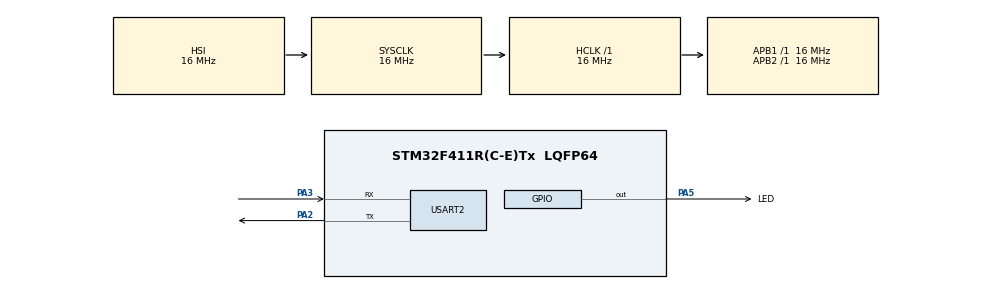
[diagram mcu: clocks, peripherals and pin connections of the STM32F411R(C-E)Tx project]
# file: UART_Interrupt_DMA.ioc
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Dma.Request0=USART2_TX
Dma.USART2_TX.0.Direction=DMA_MEMORY_TO_PERIPH
Dma.USART2_TX.0.FIFOMode=DMA_FIFOMODE_DISABLE
Dma.USART2_TX.0.Instance=DMA1_Stream6
Dma.USART2_TX.0.MemDataAlignment=DMA_MDATAALIGN_BYTE
Dma.USART2_TX.0.MemInc=DMA_MINC_ENABLE
Dma.USART2_TX.0.Mode=DMA_NORMAL
Dma.USART2_TX.0.PeriphDataAlignment=DMA_PDATAALIGN_BYTE
Dma.USART2_TX.0.PeriphInc=DMA_PINC_DISABLE
Dma.USART2_TX.0.Priority=DMA_PRIORITY_LOW
Mcu.Family=STM32F4
Mcu.Name=STM32F411R(C-E)Tx
Mcu.Package=LQFP64
NVIC.DMA1_Stream6_IRQn=true\:0\:0\:false\:false\:true\:false\:true\:true
NVIC.PriorityGroup=NVIC_PRIORITYGROUP_4
NVIC.USART2_IRQn=true\:0\:0\:false\:false\:true\:true\:true\:true
PA2.Mode=Asynchronous
PA2.Signal=USART2_TX
PA3.Mode=Asynchronous
PA3.Signal=USART2_RX
PA5.GPIO_Label=LED
PA5.Signal=GPIO_Output
ProjectManager.HeapSize=0x200
ProjectManager.StackSize=0x400
ProjectManager.TargetToolchain=STM32CubeIDE
RCC.AHBFreq_Value=16000000
RCC.APB1Freq_Value=16000000
RCC.APB2Freq_Value=16000000
RCC.CortexFreq_Value=16000000
RCC.HSE_VALUE=25000000
RCC.HSI_VALUE=16000000
RCC.LSE_VALUE=32768
RCC.SYSCLKFreq_VALUE=16000000
RCC.VCOOutputFreq_Value=192000000
USART2.VirtualMode=VM_ASYNC
board=custom

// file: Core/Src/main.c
/* USER CODE BEGIN Header */
/**
  ******************************************************************************
  * @file           : main.c
  * @brief          : Main program body
  ******************************************************************************
  * @attention
  *
  * Copyright (c) 2025 STMicroelectronics.
  * All rights reserved.
  *
  * This software is licensed under terms that can be found in the LICENSE file
  * in the root directory of this software component.
  * If no LICENSE file comes with this software, it is provided AS-IS.
  *
  ******************************************************************************
  */
/* USER CODE END Header */
#include "main.h"

/* USER CODE BEGIN Includes */
#include <stdbool.h>

/* USER CODE END Includes */

UART_HandleTypeDef huart2;
DMA_HandleTypeDef hdma_usart2_tx;

void SystemClock_Config(void);
static void MX_GPIO_Init(void);
static void MX_DMA_Init(void);
static void MX_USART2_UART_Init(void);

/* USER CODE BEGIN 0 */

uint8_t TxData[10240];
bool isSet = true; //The data is transmitted only when this flag is set

uint32_t CountInterrupts = 0;
uint32_t CountLoops = 0;

uint8_t value = 1; //Value to stuff in the array of data

//This function will be called when the the 1st half of data has been transfered.
//The 2nd half will be transfered by DMA
void HAL_UART_TxHalfCpltCallback(UART_HandleTypeDef *huart)
{
	for (uint32_t i = 0; i < 5120; ++i)
	{
		TxData[i] = value;
	}
}
//-----------------------------------------------------------
void HAL_UART_TxCpltCallback(UART_HandleTypeDef *huart)
{
	isSet = true;
	++CountInterrupts;
}
/* USER CODE END 0 */

int main(void)
{

  /* USER CODE BEGIN 1 */

	//Blocking mode (not shown) is used to send a little amount of data.
	//Interrupt mode is used to send big amount of data.
	//DMA mode is used to quick access to huge amount of data without affecting the CPU load.

  /* USER CODE END 1 */

  /* MCU Configuration--------------------------------------------------------*/

  /* Reset of all peripherals, Initializes the Flash interface and the Systick. */
  HAL_Init();

  /* Configure the system clock */
  SystemClock_Config();

  /* Initialize all configured peripherals */
  MX_GPIO_Init();
  MX_DMA_Init();
  MX_USART2_UART_Init();
  /* USER CODE BEGIN 2 */

  for (int i = 0; i < 10240; ++i)
  {
	  TxData[i] = i & (0xff);
  }

  //HAL_UART_Transmit_DMA(&huart2, TxData, 10240); //In the circular the data transfer will repeat faster than 1 s.
  //It does not affect the CPU load
  /* USER CODE END 2 */

  /* Infinite loop */
  /* USER CODE BEGIN WHILE */
  while (1)
  {
    //UART with Interrupts sends data using the CPU
	  if (isSet)
    {
    	HAL_UART_Transmit_IT(&huart2, TxData, 10240); //It tale approximately 1s to transmit the 10 Kb of data
    	isSet = false;
    }

	//UART with DMA transfers data without using the CPU and can work with huge amount of data
	if (isSet)
	{
		HAL_UART_Transmit_DMA(&huart2, TxData, 10240);
		isSet = 0;
	}
	//--------------------------------------------------------------------------------------------
    HAL_GPIO_TogglePin(GPIOA, GPIO_PIN_5);
    HAL_Delay(500);
    ++CountLoops;

    /* USER CODE END WHILE */

  }
}

void SystemClock_Config(void)
{
  RCC_OscInitTypeDef RCC_OscInitStruct = {0};
  RCC_ClkInitTypeDef RCC_ClkInitStruct = {0};

  /** Configure the main internal regulator output voltage
  */
  __HAL_RCC_PWR_CLK_ENABLE();
  __HAL_PWR_VOLTAGESCALING_CONFIG(PWR_REGULATOR_VOLTAGE_SCALE1);

  /** Initializes the RCC Oscillators according to the specified parameters
  * in the RCC_OscInitTypeDef structure.
  */
  RCC_OscInitStruct.OscillatorType = RCC_OSCILLATORTYPE_HSI;
  RCC_OscInitStruct.HSIState = RCC_HSI_ON;
  RCC_OscInitStruct.HSICalibrationValue = RCC_HSICALIBRATION_DEFAULT;
  RCC_OscInitStruct.PLL.PLLState = RCC_PLL_NONE;
  if (HAL_RCC_OscConfig(&RCC_OscInitStruct) != HAL_OK)
  {
    Error_Handler();
  }

  /** Initializes the CPU, AHB and APB buses clocks
  */
  RCC_ClkInitStruct.ClockType = RCC_CLOCKTYPE_HCLK|RCC_CLOCKTYPE_SYSCLK
                              |RCC_CLOCKTYPE_PCLK1|RCC_CLOCKTYPE_PCLK2;
  RCC_ClkInitStruct.SYSCLKSource = RCC_SYSCLKSOURCE_HSI;
  RCC_ClkInitStruct.AHBCLKDivider = RCC_SYSCLK_DIV1;
  RCC_ClkInitStruct.APB1CLKDivider = RCC_HCLK_DIV1;
  RCC_ClkInitStruct.APB2CLKDivider = RCC_HCLK_DIV1;

  if (HAL_RCC_ClockConfig(&RCC_ClkInitStruct, FLASH_LATENCY_0) != HAL_OK)
  {
    Error_Handler();
  }
}

static void MX_USART2_UART_Init(void)
{

  huart2.Instance = USART2;
  huart2.Init.BaudRate = 115200;
  huart2.Init.WordLength = UART_WORDLENGTH_8B;
  huart2.Init.StopBits = UART_STOPBITS_1;
  huart2.Init.Parity = UART_PARITY_NONE;
  huart2.Init.Mode = UART_MODE_TX_RX;
  huart2.Init.HwFlowCtl = UART_HWCONTROL_NONE;
  huart2.Init.OverSampling = UART_OVERSAMPLING_16;
  if (HAL_UART_Init(&huart2) != HAL_OK)
  {
    Error_Handler();
  }

}

static void MX_DMA_Init(void)
{

  /* DMA controller clock enable */
  __HAL_RCC_DMA1_CLK_ENABLE();

  /* DMA interrupt init */
  /* DMA1_Stream6_IRQn interrupt configuration */
  HAL_NVIC_SetPriority(DMA1_Stream6_IRQn, 0, 0);
  HAL_NVIC_EnableIRQ(DMA1_Stream6_IRQn);

}

static void MX_GPIO_Init(void)
{
  GPIO_InitTypeDef GPIO_InitStruct = {0};

  /* GPIO Ports Clock Enable */
  __HAL_RCC_GPIOA_CLK_ENABLE();

  /*Configure GPIO pin Output Level */
  HAL_GPIO_WritePin(LED_GPIO_Port, LED_Pin, GPIO_PIN_RESET);

  /*Configure GPIO pin : LED_Pin */
  GPIO_InitStruct.Pin = LED_Pin;
  GPIO_InitStruct.Mode = GPIO_MODE_OUTPUT_PP;
  GPIO_InitStruct.Pull = GPIO_NOPULL;
  GPIO_InitStruct.Speed = GPIO_SPEED_FREQ_LOW;
  HAL_GPIO_Init(LED_GPIO_Port, &GPIO_InitStruct);

}

void Error_Handler(void)
{
  __disable_irq();
  while (1)
  {
  }
}
